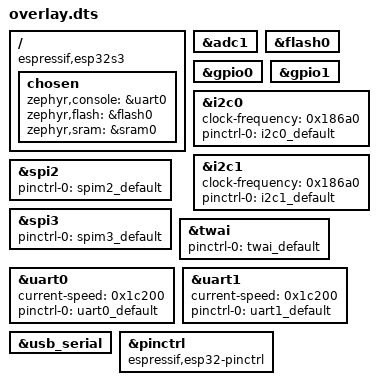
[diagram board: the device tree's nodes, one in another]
/ {
	compatible = "espressif,esp32s3";
	chosen {
		zephyr,console = &uart0;
		zephyr,flash = &flash0;
		zephyr,sram = &sram0;
	};
};
&adc1{
	status = "okay";
};
&flash0{
	status = "okay";
};
&gpio0{
	status = "okay";
};
&gpio1{
	status = "okay";
};
&i2c0{
	clock-frequency = < 0x186a0 >;
	pinctrl-0 = < &i2c0_default >;
	pinctrl-names = "default";
};
&i2c1{
	clock-frequency = < 0x186a0 >;
	pinctrl-0 = < &i2c1_default >;
	pinctrl-names = "default";
};
&spi2{
	status = "okay";
	#address-cells = < 0x1 >;
	#size-cells = < 0x0 >;
	pinctrl-0 = < &spim2_default >;
	pinctrl-names = "default";
};
&spi3{
	status = "okay";
	#address-cells = < 0x1 >;
	#size-cells = < 0x0 >;
	pinctrl-0 = < &spim3_default >;
	pinctrl-names = "default";
};
&twai{
	pinctrl-0 = < &twai_default >;
	pinctrl-names = "default";
};
&uart0{
	status = "okay";
	current-speed = < 0x1c200 >;
	pinctrl-0 = < &uart0_default >;
	pinctrl-names = "default";
};
&uart1{
	status = "okay";
	current-speed = < 0x1c200 >;
	pinctrl-0 = < &uart1_default >;
	pinctrl-names = "default";
};
&usb_serial{
	status = "okay";
};
&pinctrl{
	compatible = "espressif,esp32-pinctrl";
	status = "okay";
};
